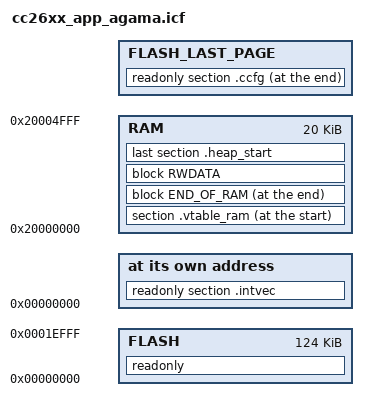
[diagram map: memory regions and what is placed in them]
/******************************************************************************

 @file  cc26xx_app_agama.icf

 @brief IAR ARM Linker Configuration File - BLE Application

        Imported Symbols
        Note: Linker defines are located in the IAR IDE project using
        --config_def in Options->Linker->Extra Options.

        CCxxxx:             Device Name (e.g. CC2650). In order to define this
                            symbol, the tool chain requires that it be set to
                            a specific value, but in fact, the actual value does
                            not matter as it is not used in the linker control
                            file. The only way this symbol is used is based on
                            whether it is defined or not, not its actual value.
                            There are other linker symbols that do specifically
                            set their value to 1 to indicate R1, and 2 to
                            indicate R2, and these values are checked and do make
                            a difference. However, it would appear confusing if
                            the device name's value did not correspond to the
                            value set in other linker symbols. In order to avoid
                            this confusion, when the symbol is defined, it should
                            be set to the value of the s ROM that it
                            corresponds so as to look and feel consistent. Please
                            note that a device name symbol should always be
                            defined to avoid side effects from default values
                            that may not be correct for the device being used.
        ICALL_RAM0_START:   RAM start of BLE stack.
        ICALL_STACK0_START: Flash start of BLE stack.
        PAGE_ALIGN:         Align the upper Flash boundry to a page boundary by
                            taking the page floor of ICALL_STACK0_START.
        USE_TIRTOS_ROM:     Defined internally in the build flow (see the end
                            of this file for more information).

        Exported Symbols
        Note: Can be used as externs in C code.

        STACK_TOP: Location of the top of RAM.

 Group: WCS, BTS
 Target Device: cc13xx_cc26xx

 ******************************************************************************
 
 Copyright (c) 2013-2022, Texas Instruments Incorporated
 All rights reserved.

 Redistribution and use in source and binary forms, with or without
 modification, are permitted provided that the following conditions
 are met:

 *  Redistributions of source code must retain the above copyright
    notice, this list of conditions and the following disclaimer.

 *  Redistributions in binary form must reproduce the above copyright
    notice, this list of conditions and the following disclaimer in the
    documentation and/or other materials provided with the distribution.

 *  Neither the name of Texas Instruments Incorporated nor the names of
    its contributors may be used to endorse or promote products derived
    from this software without specific prior written permission.

 THIS SOFTWARE IS PROVIDED BY THE COPYRIGHT HOLDERS AND CONTRIBUTORS "AS IS"
 AND ANY EXPRESS OR IMPLIED WARRANTIES, INCLUDING, BUT NOT LIMITED TO,
 THE IMPLIED WARRANTIES OF MERCHANTABILITY AND FITNESS FOR A PARTICULAR
 PURPOSE ARE DISCLAIMED. IN NO EVENT SHALL THE COPYRIGHT OWNER OR
 CONTRIBUTORS BE LIABLE FOR ANY DIRECT, INDIRECT, INCIDENTAL, SPECIAL,
 EXEMPLARY, OR CONSEQUENTIAL DAMAGES (INCLUDING, BUT NOT LIMITED TO,
 PROCUREMENT OF SUBSTITUTE GOODS OR SERVICES; LOSS OF USE, DATA, OR PROFITS;
 OR BUSINESS INTERRUPTION) HOWEVER CAUSED AND ON ANY THEORY OF LIABILITY,
 WHETHER IN CONTRACT, STRICT LIABILITY, OR TORT (INCLUDING NEGLIGENCE OR
 OTHERWISE) ARISING IN ANY WAY OUT OF THE USE OF THIS SOFTWARE,
 EVEN IF ADVISED OF THE POSSIBILITY OF SUCH DAMAGE.

 ******************************************************************************
 
 
 *****************************************************************************/

////////////////////////////////////////////////////////////////////////////////
// Memory Sizes
////////////////////////////////////////////////////////////////////////////////
define symbol FLASH_BASE            = 0x00000000;
define symbol RAM_BASE              = 0x20000000;
define symbol ROM_BASE              = 0x10000000;

if ( isdefinedsymbol(CC2650) )
{
  define symbol RAM_SIZE            = 0x00005000; // 20K
  define symbol FLASH_SIZE          = 0x00020000; // 128K
  define symbol ROM_SIZE            = 0x0001C000; // 115K
}
else if ( isdefinedsymbol(CC2642) )
{
  define symbol RAM_SIZE            = 0x00014000; // 80K
  define symbol FLASH_SIZE          = 0x00058000; // 352K
  define symbol ROM_SIZE            = 0x00040000; // 256K
}

////////////////////////////////////////////////////////////////////////////////
// Memory Definitions
////////////////////////////////////////////////////////////////////////////////

////////////////////////////////////////////////////////////////////////////////
// RAM
//
define symbol RAM_START             = RAM_BASE;
//define symbol RAM_RESERVED_START    = RAM_START + (RAM_SIZE >> 2);
define symbol RAM_RESERVED_START    = RAM_START + RAM_SIZE;

if ( isdefinedsymbol(ICALL_RAM0_START) )
{
  define symbol RAM_END             = (ICALL_RAM0_START-1);
}
else // default
{
  define symbol RAM_END             = RAM_RESERVED_START-1;
}

////////////////////////////////////////////////////////////////////////////////
// Flash
//
define symbol WORD_SIZE             = 4;

if ( isdefinedsymbol(CC2650) )
{
  define symbol PAGE_SIZE           = 0x1000;
}
else if ( isdefinedsymbol(CC2642) )
{
  define symbol PAGE_SIZE           = 0x2000;
}
export symbol PAGE_SIZE;

if (isdefinedsymbol(PAGE_ALIGN))
{
  define symbol FLASH_MEM_ALIGN     = PAGE_SIZE;
}
else
{
  define symbol FLASH_MEM_ALIGN     = WORD_SIZE;
}

define symbol FLASH_START           = FLASH_BASE;

if ( isdefinedsymbol(CC2650) )
{
  define symbol PAGE_MASK           = 0xFFFFF000;
}
else if ( isdefinedsymbol(CC2642) )
{
  define symbol PAGE_MASK           = 0xFFFFE000;
}

// Check if page alignment with the Stack image is required.
// If so, do not link into a page shared by the Stack.
if ( isdefinedsymbol(ICALL_STACK0_START) )
{
  if ( isdefinedsymbol(PAGE_ALIGN) )
  {
    define symbol ADJ_ICALL_STACK0_START = (ICALL_STACK0_START & PAGE_MASK);
  }
  else
  {
    define symbol ADJ_ICALL_STACK0_START = ICALL_STACK0_START;
  }

  define symbol FLASH_END           = (ADJ_ICALL_STACK0_START-1);
}
else // default
{
  // Default includes all but last page, which is defined later.
  define symbol FLASH_END           = FLASH_START + FLASH_SIZE - PAGE_SIZE - 1;
}

////////////////////////////////////////////////////////////////////////////////
// Stack
define symbol STACK_SIZE            = 0x400;
define symbol STACK_START           = RAM_END + 1;
define symbol STACK_END             = STACK_START - STACK_SIZE;
//
define symbol STACK_TOP             = RAM_END + 1;
export symbol STACK_TOP;

////////////////////////////////////////////////////////////////////////////////
// Flash Interrupt Vector Table
//
define symbol INTVEC_NUM_ENTRIES    = 50 + 1; // first entry is stack location
define symbol INTVEC_SIZE           = INTVEC_NUM_ENTRIES + 4;

////////////////////////////////////////////////////////////////////////////////
// Memory Regions
////////////////////////////////////////////////////////////////////////////////

define memory mem with size = 4G;

define region RAM                   = mem:[from RAM_START   to RAM_END];
define region FLASH_LAST_PAGE       = mem:[from(FLASH_SIZE - PAGE_SIZE) to FLASH_SIZE-1];
define region FLASH                 = mem:[from FLASH_START to FLASH_END] | FLASH_LAST_PAGE;

////////////////////////////////////////////////////////////////////////////////
// Memory Placement
////////////////////////////////////////////////////////////////////////////////

// Code and RO Data
place in FLASH { readonly };

// CCFG
place at end of FLASH_LAST_PAGE { readonly section .ccfg };
keep { section .ccfg };

// Interrupt Vector Table
place at address mem:FLASH_START { readonly section .intvec };
keep                             { readonly section .intvec };

// RAM Vector Table
place at start of RAM { section .vtable_ram };

// Runtime Stack
define block CSTACK with alignment = 8, size = STACK_SIZE { section .stack };

// RW Data
define block RWDATA { rw };

define section .heap_start            { public heapStart: };
define section .heap_end              { public heapEnd: };
define block   HEAP_END with size = 1 { section .heap_end };

define block END_OF_RAM with fixed order {
                                        block HEAP_END,
                                        block CSTACK
                                      };

place at end of RAM { block END_OF_RAM };

place in RAM { block RWDATA,
               last section .heap_start};

////////////////////////////////////////////////////////////////////////////////
// Initialization
////////////////////////////////////////////////////////////////////////////////

initialize by copy { readwrite };

do not initialize
{
  section .noinit,
  section .stack,
};

////////////////////////////////////////////////////////////////////////////////
// The USE_TIRTOS_ROM symbol is defined internally in the build flow (using
// --config_def USE_TIRTOS_ROM=1) for TI-RTOS applications whose appBLE.cfg file
// specifies to use the ROM.
//
if (isdefinedsymbol(USE_TIRTOS_ROM)) {
     include "TIRTOS_ROM.icf";
}

////////////////////////////////////////////////////////////////////////////////
// The following is used to Enable IAR to display RTOS ROV when auto-size heap
// is being used. it will disable the check on teh validity of the RAM address.
// if One wants to keep this check, and does not whish to use auto-size heap,
// he may comments the lines bellow.
define exported symbol __ROV_VALID_RANGE0_end__ =   RAM_BASE + RAM_SIZE;
define exported symbol __ROV_VALID_RANGE0_start__ = RAM_BASE;
